# platform_designer_hps_system_hps_0_hps register map
Vendor: default_vendor.com; File version: 0.0
Registers are 32-bit, read-write, reset 0x0 unless marked. A register's access mark holds for its fields unless they carry their own. Offsets are from the block's base; [hi:lo] are bit positions.

## gpio0 — Registers in the GPIO module
Base 0xFF708000
Same registers: gpio1 0xFF709000, gpio2 0xFF70A000
0x00 gpio_swporta_dr — This GPIO Data register is used to input or output data Check the GPIO chapter in the handbook for details on how GPIO2 is implemented.
  [28:0] gpio_swporta_dr — Values written to this register are output on the I/O signals of the GPIO Data Register, if the corresponding data direction bits for GPIO Data Direction Field are set to Output mode. The value read back is equal to the last value written to this register. Check the GPIO chapter in the handbook for details on how GPIO2 is implemented.
0x04 gpio_swporta_ddr — This register establishes the direction of each corresponding GPIO Data Field Bit. Check the GPIO chapter in the handbook for details on how GPIO2 is implemented.
  [28:0] gpio_swporta_ddr — Values written to this register independently control the direction of the corresponding data bit in the Port A Data Register. Check the GPIO chapter in the handbook for details on how GPIO2 is implemented.
    0=in; 1=out
0x30 gpio_inten — The Interrupt enable register allows interrupts for each bit of the Port A data register.
  [28:0] gpio_inten — Allows each bit of Port A Data Register to be configured for interrupt capability. Interrupts are disabled on the corresponding bits of Port A Data Register if the corresponding data direction register is set to Output.
    0=disable; 1=enable
0x34 gpio_intmask — Controls which pins cause interrupts on Port A Data Register inputs.
  [28:0] gpio_intmask — Controls whether an interrupt on Port A Data Register can generate an interrupt to the interrupt controller by not masking it. The unmasked status can be read as well as the resultant status after masking.
    0=disable; 1=enable
0x38 gpio_inttype_level — The interrupt level register defines the type of interrupt (edge or level).
  [28:0] gpio_inttype_level — This field controls the type of interrupt that can occur on the Port A Data Register.
    0=level; 1=edge
0x3C gpio_int_polarity — Controls the Polarity of Interrupts that can occur on inputs of Port A Data Register
  [28:0] gpio_int_polarity — Controls the polarity of edge or level sensitivity that can occur on input of Port A Data Register.
    0=actlow; 1=acthigh
0x40 gpio_intstatus — The Interrupt status is reported for all Port A Data Register Bits.
  [28:0] gpio_intstatus — Interrupt status of Port A Data Register.
    0=inactive; 1=active
0x44 gpio_raw_intstatus — This is the Raw Interrupt Status Register for Port A Data Register. It is used with the Interrupt Mask Register to allow interrupts from the Port A Data Register.
  [28:0] gpio_raw_intstatus — Raw interrupt of status of Port A Data Register (premasking bits)
    0=inactive; 1=active
0x48 gpio_debounce — Debounces each IO Pin
  [28:0] gpio_debounce — Controls whether an external signal that is the source of an interrupt needs to be debounced to remove any spurious glitches. A signal must be valid for two periods of an external clock (gpio_db_clk) before it is internally processed.
    0=disable; 1=enable
0x4C gpio_porta_eoi wo — Port A Data Register interrupt handling.
  [28:0] gpio_porta_eoi — Controls the clearing of edge type interrupts from the Port A Data Register.
    0=noclr; 1=clr
0x50 gpio_ext_porta ro — The external port register is used to input data to the metastability flops.
  [28:0] gpio_ext_porta — When Port A Data Register is configured as Input, then reading this location reads the values on the signals. When the data direction of Port A Data Register is set as Output, reading this location reads Port A Data Register
0x60 gpio_ls_sync — The Synchronization level register is used to synchronize input with l4_mp_clk
  [0] gpio_ls_sync — The level-sensitive interrupts is synchronized to l4_mp_clk.
    0=nosync; 1=sync
0x64 gpio_id_code ro
  [31:0] gpio_id_code — Chip identification
0x6C gpio_ver_id_code ro reset 0x3230382A — GPIO Component Version
  [31:0] gpio_ver_id_code — ASCII value for each number in the version, followed by *. For example. 32_30_31_2A represents the version 2.01
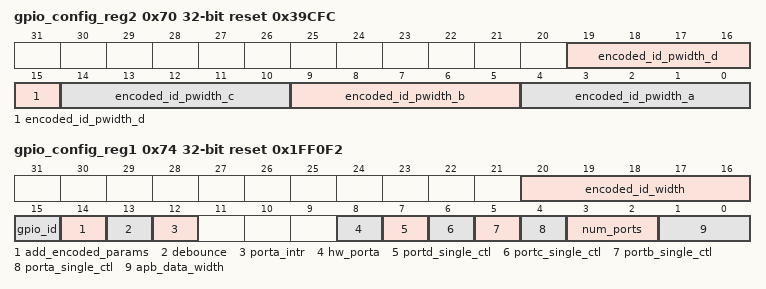
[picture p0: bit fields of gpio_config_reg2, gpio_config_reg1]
0x70 gpio_config_reg2 ro reset 0x39CFC — Specifies the bit width of port A.
  [all] fields
    7=widthlessone8bits; 28=widthlessone29bits
  [19:15] encoded_id_pwidth_d — Specifies the width of GPIO Port D. Ignored because there is no Port D in the GPIO.
  [14:10] encoded_id_pwidth_c — Specifies the width of GPIO Port C. Ignored because there is no Port C in the GPIO.
  [9:5] encoded_id_pwidth_b — Specifies the width of GPIO Port B. Ignored because there is no Port B in the GPIO.
  [4:0] encoded_id_pwidth_a — Specifies the width of GPIO Port A. The value 28 represents the 29-bit width less one.
0x74 gpio_config_reg1 ro reset 0x1FF0F2 — Reports settings of various GPIO configuration parameters
  [20:16] encoded_id_width — This value is fixed at 32 bits.
    31=encidwidth
  [15] gpio_id — Provides an ID code value
    1=idcode
  [14] add_encoded_params — Fixed to allow the indentification of the Designware IP component.
    1=addencparams
  [13] debounce — The value of this field is fixed to allow debouncing of the Port A signals.
    1=debouncea
  [12] porta_intr — The value of this field is fixed to allow interrupts on Port A.
    1=portainterr
  [8] hw_porta — The value is fixed to enable Port A configuration to be controlled by software only.
    0=portanohard
  [7] portd_single_ctl — Indicates the mode of operation of Port D to be software controlled only. Ignored because there is no Port D in the GPIO.
    1=softctlonly
  [6] portc_single_ctl — Indicates the mode of operation of Port C to be software controlled only. Ignored because there is no Port C in the GPIO.
    1=softctlonly
  [5] portb_single_ctl — Indicates the mode of operation of Port B to be software controlled only. Ignored because there is no Port B in the GPIO.
    1=softctlonly
  [4] porta_single_ctl — Indicates the mode of operation of Port A to be software controlled only.
    1=softctlonly
  [3:2] num_ports — The value of this register is fixed at one port (Port A).
    0=oneporta
  [1:0] apb_data_width — Fixed to support an ABP data bus width of 32-bits.
    2=width32bits
